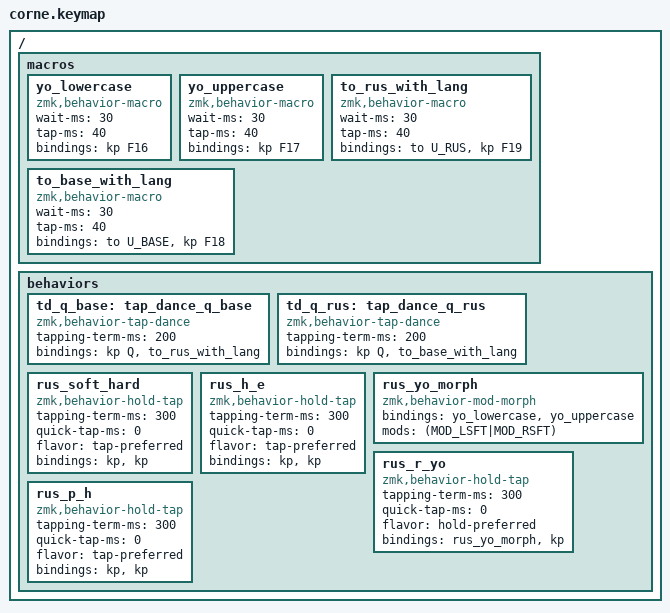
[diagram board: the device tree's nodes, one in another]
// Copyright 2021 Manna Harbour
// https://github.com/manna-harbour/miryoku

#include "../miryoku/custom_config.h"
#include "../miryoku/mapping/42/corne.h"
#include "../miryoku/miryoku.dtsi"

/ {
    macros {
        // Macro for ё: send F16 (will be converted to ё by Karabiner)
        yo_lowercase: yo_lowercase {
            compatible = "zmk,behavior-macro";
            #binding-cells = <0>;
            wait-ms = <30>;
            tap-ms = <40>;
            bindings = <&kp F16>;
        };
        
        // Macro for Ё: send F17 (will be converted to Ё by Karabiner)
        yo_uppercase: yo_uppercase {
            compatible = "zmk,behavior-macro";
            #binding-cells = <0>;
            wait-ms = <30>;
            tap-ms = <40>;
            bindings = <&kp F17>;
        };
        
        // Macro: switch to RUS layer + F19 for Russian layout (via Karabiner)
        to_rus_with_lang: to_rus_with_lang {
            compatible = "zmk,behavior-macro";
            #binding-cells = <0>;
            wait-ms = <30>;
            tap-ms = <40>;
            bindings = <&to U_RUS>, <&kp F19>;
        };
        
        // Macro: switch to BASE layer + F18 for English layout (via Karabiner)
        to_base_with_lang: to_base_with_lang {
            compatible = "zmk,behavior-macro";
            #binding-cells = <0>;
            wait-ms = <30>;
            tap-ms = <40>;
            bindings = <&to U_BASE>, <&kp F18>;
        };
    };
    
    behaviors {
        // Tap-dance for Q on BASE layer: single tap = Q, double tap = switch to RUS + Globe
        td_q_base: tap_dance_q_base {
            compatible = "zmk,behavior-tap-dance";
            #binding-cells = <0>;
            tapping-term-ms = <200>;
            bindings = <&kp Q>, <&to_rus_with_lang>;
        };
        
        // Tap-dance for Q on RUS layer: single tap = Q, double tap = switch to BASE + Globe
        td_q_rus: tap_dance_q_rus {
            compatible = "zmk,behavior-tap-dance";
            #binding-cells = <0>;
            tapping-term-ms = <200>;
            bindings = <&kp Q>, <&to_base_with_lang>;
        };
        
        // Hold-tap for soft sign -> hard sign (ь -> ъ)
        rus_soft_hard: rus_soft_hard {
            compatible = "zmk,behavior-hold-tap";
            #binding-cells = <2>;
            tapping-term-ms = <300>;
            quick-tap-ms = <0>;
            flavor = "tap-preferred";
            bindings = <&kp>, <&kp>;
        };
        
        // Hold-tap for H -> E with apostrophe (э)
        rus_h_e: rus_h_e {
            compatible = "zmk,behavior-hold-tap";
            #binding-cells = <2>;
            tapping-term-ms = <300>;
            quick-tap-ms = <0>;
            flavor = "tap-preferred";
            bindings = <&kp>, <&kp>;
        };
        
        // Mod-morph for R -> ё/Ё (F16 without shift, F17 with shift)
        rus_yo_morph: rus_yo_morph {
            compatible = "zmk,behavior-mod-morph";
            #binding-cells = <0>;
            bindings = <&yo_lowercase>, <&yo_uppercase>;
            mods = <(MOD_LSFT|MOD_RSFT)>;
        };
        
        // Hold-tap for R -> ё on hold  
        rus_r_yo: rus_r_yo {
            compatible = "zmk,behavior-hold-tap";
            #binding-cells = <2>;
            tapping-term-ms = <300>;
            quick-tap-ms = <0>;
            flavor = "hold-preferred";
            bindings = <&rus_yo_morph>, <&kp>;
        };
        
        // Hold-tap for P -> х (h) on hold
        rus_p_h: rus_p_h {
            compatible = "zmk,behavior-hold-tap";
            #binding-cells = <2>;
            tapping-term-ms = <300>;
            quick-tap-ms = <0>;
            flavor = "tap-preferred";
            bindings = <&kp>, <&kp>;
        };
        
    };
    
};
